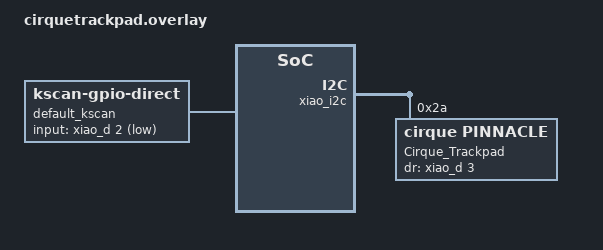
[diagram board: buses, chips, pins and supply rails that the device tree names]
// cirquetrackpad.overlay

/ {
    chosen {
        zmk,kscan = &default_kscan;
    };

    default_kscan: kscan {
        compatible = "zmk,kscan-gpio-direct";
        label = "default_kscan";

        input-gpios
            = <&xiao_d 2 (GPIO_ACTIVE_LOW | GPIO_PULL_UP)> // Row A from the schematic file
            //, <&xiao_d 1 (GPIO_ACTIVE_LOW | GPIO_PULL_UP)> // Row B from the schematic file
            //, <&xiao_d 0 (GPIO_ACTIVE_LOW | GPIO_PULL_UP)> // Row C from the schematic file
            ;

    };
};

&xiao_i2c {
    status = "okay";
    trackpad@2a {
	    compatible = "cirque,pinnacle";
	    reg = <0x2a>;
	    label = "Cirque_Trackpad";
        dr-gpios = <&xiao_d	3	GPIO_ACTIVE_HIGH>;
	    rotate-90;
	    //sleep;
	    //no-taps;
    };
};
